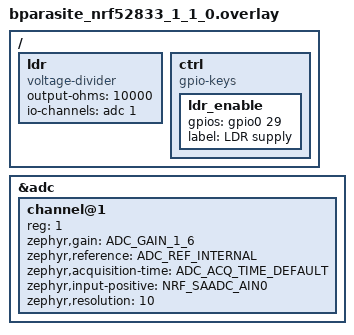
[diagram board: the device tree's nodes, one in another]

/ {
	// Light dependant resistor.
	ldr: ldr {
		compatible = "voltage-divider";
		output-ohms = <10000>;
		io-channels = <&adc 1>;
	};

	ctrl {
		compatible = "gpio-keys";
		ldr_enable: ldr_enable {
			// P0.29.
			gpios = <&gpio0 29 GPIO_ACTIVE_HIGH>;
			label = "LDR supply";
		};
	};
};

&adc {
	channel@1 {
		reg = <1>;
		zephyr,gain = "ADC_GAIN_1_6";
		zephyr,reference = "ADC_REF_INTERNAL";
		zephyr,acquisition-time = <ADC_ACQ_TIME_DEFAULT>;
		// P0.02.
		zephyr,input-positive = <NRF_SAADC_AIN0>;
		zephyr,resolution = <10>;
	};
};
